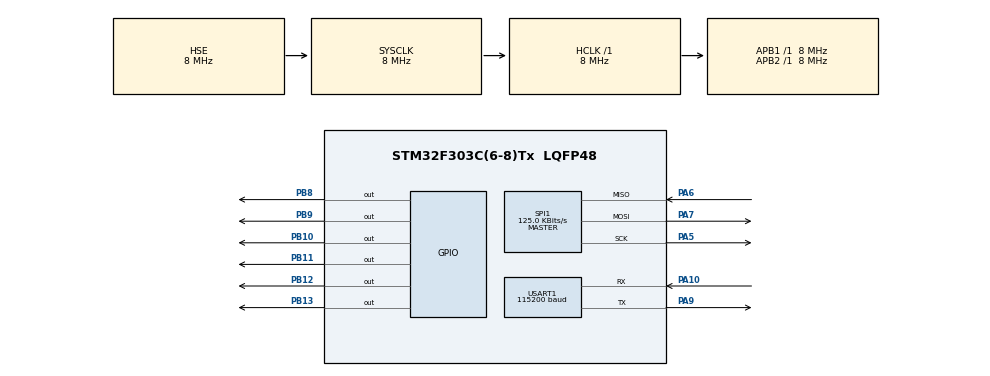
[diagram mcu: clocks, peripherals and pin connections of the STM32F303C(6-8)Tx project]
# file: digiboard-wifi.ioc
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Mcu.Family=STM32F3
Mcu.Name=STM32F303C(6-8)Tx
Mcu.Package=LQFP48
NVIC.PriorityGroup=NVIC_PRIORITYGROUP_4
NVIC.USART1_IRQn=true\:0\:0\:false\:false\:true\:true
PA10.Mode=Asynchronous
PA10.Signal=USART1_RX
PA5.Mode=Full_Duplex_Master
PA5.Signal=SPI1_SCK
PA6.Mode=Full_Duplex_Master
PA6.Signal=SPI1_MISO
PA7.Mode=Full_Duplex_Master
PA7.Signal=SPI1_MOSI
PA9.Mode=Asynchronous
PA9.Signal=USART1_TX
PB10.Signal=GPIO_Output
PB11.Signal=GPIO_Output
PB12.Signal=GPIO_Output
PB13.Signal=GPIO_Output
PB8.Signal=GPIO_Output
PB9.Signal=GPIO_Output
PF0\ /\ OSC_IN.Mode=HSE-External-Oscillator
PF0\ /\ OSC_IN.Signal=RCC_OSC_IN
PF1\ /\ OSC_OUT.Mode=HSE-External-Oscillator
PF1\ /\ OSC_OUT.Signal=RCC_OSC_OUT
ProjectManager.HeapSize=0x200
ProjectManager.StackSize=0x400
ProjectManager.TargetToolchain=EWARM
RCC.AHBFreq_Value=8000000
RCC.APB1Freq_Value=8000000
RCC.APB1TimFreq_Value=8000000
RCC.APB2Freq_Value=8000000
RCC.APB2TimFreq_Value=8000000
RCC.CortexFreq_Value=8000000
RCC.HCLKFreq_Value=8000000
RCC.HSE_VALUE=8000000
RCC.HSI_VALUE=8000000
RCC.LSE_VALUE=32768
RCC.PLLMUL=RCC_PLL_MUL4
RCC.PLLSourceVirtual=RCC_PLLSOURCE_HSE
RCC.SYSCLKFreq_VALUE=8000000
RCC.SYSCLKSourceVirtual=RCC_SYSCLKSOURCE_HSE
SPI1.BaudRatePrescaler=SPI_BAUDRATEPRESCALER_64
SPI1.CLKPhase=SPI_PHASE_2EDGE
SPI1.CLKPolarity=SPI_POLARITY_HIGH
SPI1.CalculateBaudRate=125.0 KBits/s
SPI1.DataSize=SPI_DATASIZE_8BIT
SPI1.Direction=SPI_DIRECTION_2LINES
SPI1.FirstBit=SPI_FIRSTBIT_LSB
SPI1.Mode=SPI_MODE_MASTER
SPI1.VirtualType=VM_MASTER
USART1.BaudRate=115200
USART1.VirtualMode-Asynchronous=VM_ASYNC
USART1.WordLength=WORDLENGTH_8B
board=digiboard-wifi

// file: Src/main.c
/**
  ******************************************************************************
  * File Name          : main.c
  * Description        : Main program body
  ******************************************************************************
  ** This notice applies to any and all portions of this file
  * that are not between comment pairs USER CODE BEGIN and
  * USER CODE END. Other portions of this file, whether
  * inserted by the user or by software development tools
  * are owned by their respective copyright owners.
  *
  * COPYRIGHT(c) 2018 STMicroelectronics
  *
  * Redistribution and use in source and binary forms, with or without modification,
  * are permitted provided that the following conditions are met:
  *   1. Redistributions of source code must retain the above copyright notice,
  *      this list of conditions and the following disclaimer.
  *   2. Redistributions in binary form must reproduce the above copyright notice,
  *      this list of conditions and the following disclaimer in the documentation
  *      and/or other materials provided with the distribution.
  *   3. Neither the name of STMicroelectronics nor the names of its contributors
  *      may be used to endorse or promote products derived from this software
  *      without specific prior written permission.
  *
  * THIS SOFTWARE IS PROVIDED BY THE COPYRIGHT HOLDERS AND CONTRIBUTORS "AS IS"
  * AND ANY EXPRESS OR IMPLIED WARRANTIES, INCLUDING, BUT NOT LIMITED TO, THE
  * IMPLIED WARRANTIES OF MERCHANTABILITY AND FITNESS FOR A PARTICULAR PURPOSE ARE
  * DISCLAIMED. IN NO EVENT SHALL THE COPYRIGHT HOLDER OR CONTRIBUTORS BE LIABLE
  * FOR ANY DIRECT, INDIRECT, INCIDENTAL, SPECIAL, EXEMPLARY, OR CONSEQUENTIAL
  * DAMAGES (INCLUDING, BUT NOT LIMITED TO, PROCUREMENT OF SUBSTITUTE GOODS OR
  * SERVICES; LOSS OF USE, DATA, OR PROFITS; OR BUSINESS INTERRUPTION) HOWEVER
  * CAUSED AND ON ANY THEORY OF LIABILITY, WHETHER IN CONTRACT, STRICT LIABILITY,
  * OR TORT (INCLUDING NEGLIGENCE OR OTHERWISE) ARISING IN ANY WAY OUT OF THE USE
  * OF THIS SOFTWARE, EVEN IF ADVISED OF THE POSSIBILITY OF SUCH DAMAGE.
  *
  ******************************************************************************
  */

#include "main.h"
#include "stm32f3xx_hal.h"
#include "spi.h"
#include "usart.h"
#include "gpio.h"

/* USER CODE BEGIN Includes */
#include "displayMethods.h"
#include "stdint.h"
#include "string.h"
#include "stdio.h"
#include "math.h"
#include "readWifi.h"
#include "initWifi.h"

/* USER CODE END Includes */

/* USER CODE BEGIN PV */

/* Private variables ---------------------------------------------------------*/

/* USER CODE END PV */

void SystemClock_Config(void);

/* USER CODE BEGIN PFP */
/* Private function prototypes -----------------------------------------------*/

/* USER CODE END PFP */

int main(void)
{

  /* MCU Configuration----------------------------------------------------------*/

  /* Reset of all peripherals, Initializes the Flash interface and the Systick. */
  HAL_Init();

  /* Configure the system clock */
  SystemClock_Config();

  /* Initialize all configured peripherals */
  MX_GPIO_Init();
  MX_SPI1_Init();
  MX_USART1_UART_Init();

  /* USER CODE BEGIN 2 */
  displayInit();
  /* Wait for the end of the transfer*/

  /* USER CODE END 2 */

  /* Infinite loop */
  /* USER CODE BEGIN WHILE */

  while (1)
  {
      readUartIT();
      printf("\r\n1");
      clearBufferIT();

  /* USER CODE END WHILE */

  }

}

/** System Clock Configuration
*/
void SystemClock_Config(void)
{

  RCC_OscInitTypeDef RCC_OscInitStruct;
  RCC_ClkInitTypeDef RCC_ClkInitStruct;
  RCC_PeriphCLKInitTypeDef PeriphClkInit;

    /**Initializes the CPU, AHB and APB busses clocks
    */
  RCC_OscInitStruct.OscillatorType = RCC_OSCILLATORTYPE_HSE;
  RCC_OscInitStruct.HSEState = RCC_HSE_ON;
  RCC_OscInitStruct.HSIState = RCC_HSI_ON;
  RCC_OscInitStruct.PLL.PLLState = RCC_PLL_NONE;
  if (HAL_RCC_OscConfig(&RCC_OscInitStruct) != HAL_OK)
  {
    _Error_Handler(__FILE__, __LINE__);
  }

    /**Initializes the CPU, AHB and APB busses clocks
    */
  RCC_ClkInitStruct.ClockType = RCC_CLOCKTYPE_HCLK|RCC_CLOCKTYPE_SYSCLK
                              |RCC_CLOCKTYPE_PCLK1|RCC_CLOCKTYPE_PCLK2;
  RCC_ClkInitStruct.SYSCLKSource = RCC_SYSCLKSOURCE_HSE;
  RCC_ClkInitStruct.AHBCLKDivider = RCC_SYSCLK_DIV1;
  RCC_ClkInitStruct.APB1CLKDivider = RCC_HCLK_DIV1;
  RCC_ClkInitStruct.APB2CLKDivider = RCC_HCLK_DIV1;

  if (HAL_RCC_ClockConfig(&RCC_ClkInitStruct, FLASH_LATENCY_0) != HAL_OK)
  {
    _Error_Handler(__FILE__, __LINE__);
  }

  PeriphClkInit.PeriphClockSelection = RCC_PERIPHCLK_USART1;
  PeriphClkInit.Usart1ClockSelection = RCC_USART1CLKSOURCE_PCLK1;
  if (HAL_RCCEx_PeriphCLKConfig(&PeriphClkInit) != HAL_OK)
  {
    _Error_Handler(__FILE__, __LINE__);
  }

    /**Configure the Systick interrupt time
    */
  HAL_SYSTICK_Config(HAL_RCC_GetHCLKFreq()/1000);

    /**Configure the Systick
    */
  HAL_SYSTICK_CLKSourceConfig(SYSTICK_CLKSOURCE_HCLK);

  /* SysTick_IRQn interrupt configuration */
  HAL_NVIC_SetPriority(SysTick_IRQn, 0, 0);
}

void _Error_Handler(char * file, int line)
{
  while(1)
  {
  }
}

/************************ (C) COPYRIGHT STMicroelectronics *****END OF FILE****/
